AUTOSAR XML (schema 4-0-3)
package /ComponentTypes
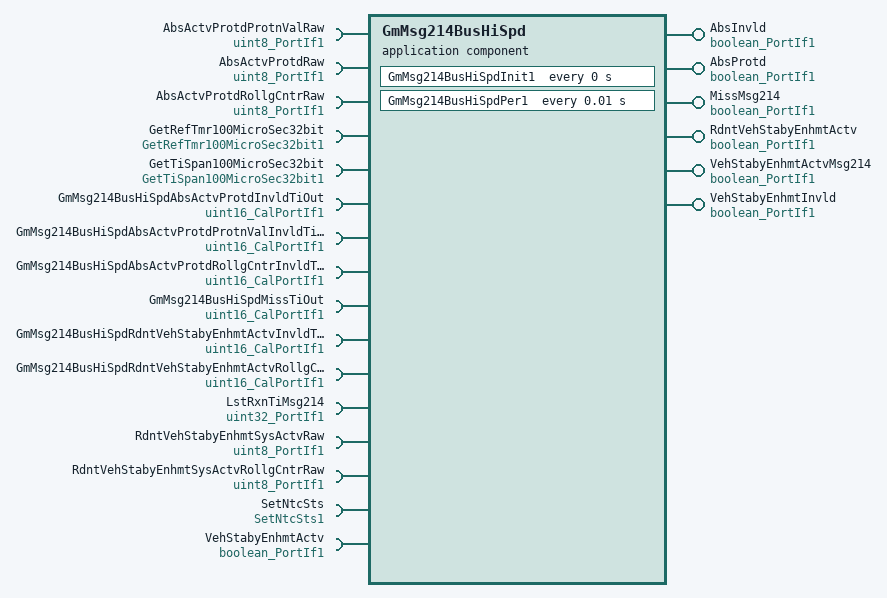
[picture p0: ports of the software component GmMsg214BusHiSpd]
  application sw component type GmMsg214BusHiSpd
    6 x provide port, all with nonqueued-sender-com-spec{data-element=Logl, init-value=0}, provided-interface=boolean_PortIf1:
      AbsInvld
      AbsProtd
      MissMsg214
      RdntVehStabyEnhmtActv
      VehStabyEnhmtActvMsg214
      VehStabyEnhmtInvld
    16 x require port:
      AbsActvProtdProtnValRaw: nonqueued-receiver-com-spec{data-element=Val, filter=data-filter-type=ALWAYS, init-value=0}, required-interface=uint8_PortIf1
      AbsActvProtdRaw: nonqueued-receiver-com-spec{data-element=Val, filter=data-filter-type=ALWAYS, init-value=0}, required-interface=uint8_PortIf1
      AbsActvProtdRollgCntrRaw: nonqueued-receiver-com-spec{data-element=Val, filter=data-filter-type=ALWAYS, init-value=0}, required-interface=uint8_PortIf1
      GetRefTmr100MicroSec32bit: required-interface=GetRefTmr100MicroSec32bit1
      GetTiSpan100MicroSec32bit: required-interface=GetTiSpan100MicroSec32bit1
      GmMsg214BusHiSpdAbsActvProtdInvldTiOut: parameter-require-com-spec{init-value=500, parameter=Val}, required-interface=uint16_CalPortIf1
      GmMsg214BusHiSpdAbsActvProtdProtnValInvldTiOut: parameter-require-com-spec{init-value=500, parameter=Val}, required-interface=uint16_CalPortIf1
      GmMsg214BusHiSpdAbsActvProtdRollgCntrInvldTiOut: parameter-require-com-spec{init-value=500, parameter=Val}, required-interface=uint16_CalPortIf1
      GmMsg214BusHiSpdMissTiOut: parameter-require-com-spec{init-value=500, parameter=Val}, required-interface=uint16_CalPortIf1
      GmMsg214BusHiSpdRdntVehStabyEnhmtActvInvldTiOut: parameter-require-com-spec{init-value=500, parameter=Val}, required-interface=uint16_CalPortIf1
      GmMsg214BusHiSpdRdntVehStabyEnhmtActvRollgCntrInvldTiOut: parameter-require-com-spec{init-value=500, parameter=Val}, required-interface=uint16_CalPortIf1
      LstRxnTiMsg214: nonqueued-receiver-com-spec{data-element=Val, filter=data-filter-type=ALWAYS, init-value=0}, required-interface=uint32_PortIf1
      RdntVehStabyEnhmtSysActvRaw: nonqueued-receiver-com-spec{data-element=Val, filter=data-filter-type=ALWAYS, init-value=0}, required-interface=uint8_PortIf1
      RdntVehStabyEnhmtSysActvRollgCntrRaw: nonqueued-receiver-com-spec{data-element=Val, filter=data-filter-type=ALWAYS, init-value=0}, required-interface=uint8_PortIf1
      SetNtcSts: required-interface=SetNtcSts1
      VehStabyEnhmtActv: nonqueued-receiver-com-spec{data-element=Logl, filter=data-filter-type=ALWAYS, init-value=0}, required-interface=boolean_PortIf1
    behavior GmMsg214BusHiSpd_InternalBehavior: data-type-mapping=Nexteer
      ar-typed-per-instance-memorys:
        11 x data, all with sw-calibration-access=READ-ONLY:
          GmMsg214BusHiSpdAbsActvProtdInvldProtnValTmr: type=uint32
          GmMsg214BusHiSpdAbsActvProtdInvldRollgCntrTmr: type=uint32
          GmMsg214BusHiSpdAbsActvProtdInvldTmr: type=uint32
          GmMsg214BusHiSpdAbsActvProtdPrevRollgCntrVal: type=uint8
          GmMsg214BusHiSpdPrevAbsProtd: type=boolean
          GmMsg214BusHiSpdPrevRxnTi: type=uint32
          GmMsg214BusHiSpdPrevVehStabyEnhmtInvld: type=boolean
          GmMsg214BusHiSpdRdntVehStabyEnhmtInvldRollgCntrTmr: type=uint32
          GmMsg214BusHiSpdRdntVehStabyEnhmtInvldTmr: type=uint32
          GmMsg214BusHiSpdRdntVehStabyEnhmtPrevRollgCntrVal: type=uint8
          GmMsg214BusHiSpdRollgCntrRst: type=boolean
      timing event GmMsg214BusHiSpd_InitEvent: start-on-event=GmMsg214BusHiSpdInit1, period=0
      timing event TMT_GM0C9HSPer1: start-on-event=GmMsg214BusHiSpdPer1, period=0.01
      runnable GmMsg214BusHiSpdInit1
      runnable GmMsg214BusHiSpdPer1
        data-receive-point-by-arguments:
          7 x access:
            REC_AbsActvProtdProtnValRaw_Val: accessed-variable=AbsActvProtdProtnValRaw.Val
            REC_AbsActvProtdRaw_Val: accessed-variable=AbsActvProtdRaw.Val
            REC_AbsActvProtdRollgCntrRaw_Val: accessed-variable=AbsActvProtdRollgCntrRaw.Val
            REC_Msg0C9HSLstRxnTi_Val: accessed-variable=LstRxnTiMsg214.Val
            REC_RdntVehStabyEnhmtSysActvRaw_Val: accessed-variable=RdntVehStabyEnhmtSysActvRaw.Val
            REC_RdntVehStabyEnhmtSysActvRollgCntrRaw_Val: accessed-variable=RdntVehStabyEnhmtSysActvRollgCntrRaw.Val
            REC_VehStabyEnhmtActv_Logl: accessed-variable=VehStabyEnhmtActv.Logl
        data-send-points:
          6 x access:
            SEND_AbsInvld_Logl: accessed-variable=AbsInvld.Logl
            SEND_AbsProtd_Logl: accessed-variable=AbsProtd.Logl
            SEND_MissMsg214_Logl: accessed-variable=MissMsg214.Logl
            SEND_RdntVehStabyEnhmtActv_Logl: accessed-variable=RdntVehStabyEnhmtActv.Logl
            SEND_VehStabyEnhmtActvMsg214_Logl: accessed-variable=VehStabyEnhmtActvMsg214.Logl
            SEND_VehStabyEnhmtInvld_Logl: accessed-variable=VehStabyEnhmtInvld.Logl
        sync call SC_GetRefTmr100MicroSec32bit_Oper: operation=GetRefTmr100MicroSec32bit.Oper, timeout=0
        sync call SC_GetTiSpan100MicroSec32bit_Oper: operation=GetTiSpan100MicroSec32bit.Oper, timeout=0
        sync call SC_SetNtcSts_Oper: operation=SetNtcSts.Oper, timeout=0
  swc implementation GmMsg214BusHiSpd_Implementation: behavior=GmMsg214BusHiSpd_InternalBehavior
    code-descriptors:
      code Default: artifact-descriptors=autosar-engineering-object={short-label=Default, category=SWSRC}
